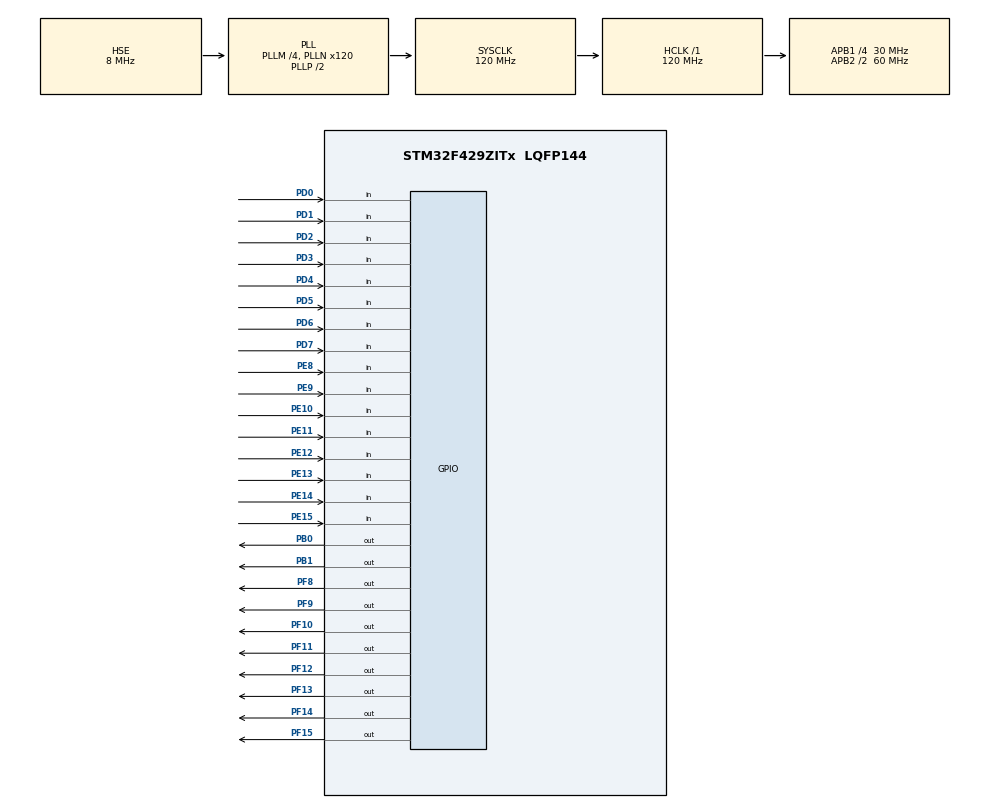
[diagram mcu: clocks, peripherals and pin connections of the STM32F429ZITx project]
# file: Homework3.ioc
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Mcu.Family=STM32F4
Mcu.Name=STM32F429ZITx
Mcu.Package=LQFP144
NVIC.PriorityGroup=NVIC_PRIORITYGROUP_4
NVIC.RCC_IRQn=true\:0\:0\:false\:false\:true\:true\:false\:true
PB0.Signal=GPIO_Output
PB1.Signal=GPIO_Output
PD0.Signal=GPIO_Input
PD1.Signal=GPIO_Input
PD2.Signal=GPIO_Input
PD3.Signal=GPIO_Input
PD4.Signal=GPIO_Input
PD5.Signal=GPIO_Input
PD6.Signal=GPIO_Input
PD7.Signal=GPIO_Input
PE10.Signal=GPIO_Input
PE11.Signal=GPIO_Input
PE12.Signal=GPIO_Input
PE13.Signal=GPIO_Input
PE14.Signal=GPIO_Input
PE15.Signal=GPIO_Input
PE8.Signal=GPIO_Input
PE9.Signal=GPIO_Input
PF10.Signal=GPIO_Output
PF11.Signal=GPIO_Output
PF12.Signal=GPIO_Output
PF13.Signal=GPIO_Output
PF14.Signal=GPIO_Output
PF15.Signal=GPIO_Output
PF8.Signal=GPIO_Output
PF9.Signal=GPIO_Output
PH0/OSC_IN.Mode=HSE-External-Oscillator
PH0/OSC_IN.Signal=RCC_OSC_IN
PH1/OSC_OUT.Mode=HSE-External-Oscillator
PH1/OSC_OUT.Signal=RCC_OSC_OUT
ProjectManager.HeapSize=0x200
ProjectManager.StackSize=0x400
ProjectManager.TargetToolchain=EWARM V8.50
RCC.48MHZClocksFreq_Value=60000000
RCC.AHBFreq_Value=120000000
RCC.APB1CLKDivider=RCC_HCLK_DIV4
RCC.APB1Freq_Value=30000000
RCC.APB1TimFreq_Value=60000000
RCC.APB2CLKDivider=RCC_HCLK_DIV2
RCC.APB2Freq_Value=60000000
RCC.APB2TimFreq_Value=120000000
RCC.CortexFreq_Value=120000000
RCC.HCLKFreq_Value=120000000
RCC.HSE_VALUE=8000000
RCC.HSI_VALUE=16000000
RCC.LSE_VALUE=32768
RCC.PLLM=4
RCC.PLLN=120
RCC.PLLSourceVirtual=RCC_PLLSOURCE_HSE
RCC.RCC_MCO1Source=RCC_MCO1SOURCE_PLLCLK
RCC.RCC_MCODiv1=RCC_MCODIV_2
RCC.SYSCLKFreq_VALUE=120000000
RCC.SYSCLKSource=RCC_SYSCLKSOURCE_PLLCLK
RCC.VCOOutputFreq_Value=240000000
board=custom

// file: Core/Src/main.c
/* USER CODE BEGIN Header */
/**
  ******************************************************************************
  * @file           : main.c
  * @brief          : Main program body
  ******************************************************************************
  * @attention
  *
  * Copyright (c) 2023 STMicroelectronics.
  * All rights reserved.
  *
  * This software is licensed under terms that can be found in the LICENSE file
  * in the root directory of this software component.
  * If no LICENSE file comes with this software, it is provided AS-IS.
  *
  ******************************************************************************
  */
/* USER CODE END Header */
#include "main.h"

/* USER CODE BEGIN PV */
uint16_t a = 0;  //an operand
uint16_t b = 0;  // the other operand
uint16_t answer = 0;  // the answer to output
// the ovf flag will be output on pin PB0
/* USER CODE END PV */

void SystemClock_Config(void);
static void MX_GPIO_Init(void);

int main(void)
{

  /* MCU Configuration--------------------------------------------------------*/

  /* Reset of all peripherals, Initializes the Flash interface and the Systick. */
  HAL_Init();

  /* Configure the system clock */
  SystemClock_Config();

  /* Initialize all configured peripherals */
  MX_GPIO_Init();

  /* Infinite loop */
  /* USER CODE BEGIN WHILE */
  SysTick_Config(2400000); // The number of ticks that correspond to an interrupt once about every 20 ms by setting up SYSCLK to 120MHz
  while (1)
  {
    /* USER CODE END WHILE */

  }
}

void SystemClock_Config(void)
{
  RCC_OscInitTypeDef RCC_OscInitStruct = {0};
  RCC_ClkInitTypeDef RCC_ClkInitStruct = {0};

  /** Configure the main internal regulator output voltage
  */
  __HAL_RCC_PWR_CLK_ENABLE();
  __HAL_PWR_VOLTAGESCALING_CONFIG(PWR_REGULATOR_VOLTAGE_SCALE3);

  /** Initializes the RCC Oscillators according to the specified parameters
  * in the RCC_OscInitTypeDef structure.
  */
  RCC_OscInitStruct.OscillatorType = RCC_OSCILLATORTYPE_HSE;
  RCC_OscInitStruct.HSEState = RCC_HSE_ON;
  RCC_OscInitStruct.PLL.PLLState = RCC_PLL_ON;
  RCC_OscInitStruct.PLL.PLLSource = RCC_PLLSOURCE_HSE;
  RCC_OscInitStruct.PLL.PLLM = 4;
  RCC_OscInitStruct.PLL.PLLN = 120;
  RCC_OscInitStruct.PLL.PLLP = RCC_PLLP_DIV2;
  RCC_OscInitStruct.PLL.PLLQ = 4;
  if (HAL_RCC_OscConfig(&RCC_OscInitStruct) != HAL_OK)
  {
    Error_Handler();
  }

  /** Initializes the CPU, AHB and APB buses clocks
  */
  RCC_ClkInitStruct.ClockType = RCC_CLOCKTYPE_HCLK|RCC_CLOCKTYPE_SYSCLK
                              |RCC_CLOCKTYPE_PCLK1|RCC_CLOCKTYPE_PCLK2;
  RCC_ClkInitStruct.SYSCLKSource = RCC_SYSCLKSOURCE_PLLCLK;
  RCC_ClkInitStruct.AHBCLKDivider = RCC_SYSCLK_DIV1;
  RCC_ClkInitStruct.APB1CLKDivider = RCC_HCLK_DIV4;
  RCC_ClkInitStruct.APB2CLKDivider = RCC_HCLK_DIV2;

  if (HAL_RCC_ClockConfig(&RCC_ClkInitStruct, FLASH_LATENCY_3) != HAL_OK)
  {
    Error_Handler();
  }
}

static void MX_GPIO_Init(void)
{
  GPIO_InitTypeDef GPIO_InitStruct = {0};

  /* GPIO Ports Clock Enable */
  __HAL_RCC_GPIOF_CLK_ENABLE();
  __HAL_RCC_GPIOH_CLK_ENABLE();
  __HAL_RCC_GPIOB_CLK_ENABLE();
  __HAL_RCC_GPIOE_CLK_ENABLE();
  __HAL_RCC_GPIOD_CLK_ENABLE();

  /*Configure GPIO pin Output Level */
  HAL_GPIO_WritePin(GPIOF, GPIO_PIN_8|GPIO_PIN_9|GPIO_PIN_10|GPIO_PIN_11
                          |GPIO_PIN_12|GPIO_PIN_13|GPIO_PIN_14|GPIO_PIN_15, GPIO_PIN_RESET);

  /*Configure GPIO pin Output Level */
  HAL_GPIO_WritePin(GPIOB, GPIO_PIN_0|GPIO_PIN_1, GPIO_PIN_RESET);

  /*Configure GPIO pins : PF8 PF9 PF10 PF11
                           PF12 PF13 PF14 PF15 */
  GPIO_InitStruct.Pin = GPIO_PIN_8|GPIO_PIN_9|GPIO_PIN_10|GPIO_PIN_11
                          |GPIO_PIN_12|GPIO_PIN_13|GPIO_PIN_14|GPIO_PIN_15;
  GPIO_InitStruct.Mode = GPIO_MODE_OUTPUT_PP;
  GPIO_InitStruct.Pull = GPIO_NOPULL;
  GPIO_InitStruct.Speed = GPIO_SPEED_FREQ_LOW;
  HAL_GPIO_Init(GPIOF, &GPIO_InitStruct);

  /*Configure GPIO pins : PB0 PB1 */
  GPIO_InitStruct.Pin = GPIO_PIN_0|GPIO_PIN_1;
  GPIO_InitStruct.Mode = GPIO_MODE_OUTPUT_PP;
  GPIO_InitStruct.Pull = GPIO_NOPULL;
  GPIO_InitStruct.Speed = GPIO_SPEED_FREQ_LOW;
  HAL_GPIO_Init(GPIOB, &GPIO_InitStruct);

  /*Configure GPIO pins : PE8 PE9 PE10 PE11
                           PE12 PE13 PE14 PE15 */
  GPIO_InitStruct.Pin = GPIO_PIN_8|GPIO_PIN_9|GPIO_PIN_10|GPIO_PIN_11
                          |GPIO_PIN_12|GPIO_PIN_13|GPIO_PIN_14|GPIO_PIN_15;
  GPIO_InitStruct.Mode = GPIO_MODE_INPUT;
  GPIO_InitStruct.Pull = GPIO_NOPULL;
  HAL_GPIO_Init(GPIOE, &GPIO_InitStruct);

  /*Configure GPIO pins : PD0 PD1 PD2 PD3
                           PD4 PD5 PD6 PD7 */
  GPIO_InitStruct.Pin = GPIO_PIN_0|GPIO_PIN_1|GPIO_PIN_2|GPIO_PIN_3
                          |GPIO_PIN_4|GPIO_PIN_5|GPIO_PIN_6|GPIO_PIN_7;
  GPIO_InitStruct.Mode = GPIO_MODE_INPUT;
  GPIO_InitStruct.Pull = GPIO_NOPULL;
  HAL_GPIO_Init(GPIOD, &GPIO_InitStruct);

}

void Error_Handler(void)
{
  __disable_irq();
  while (1)
  {
  }
}
